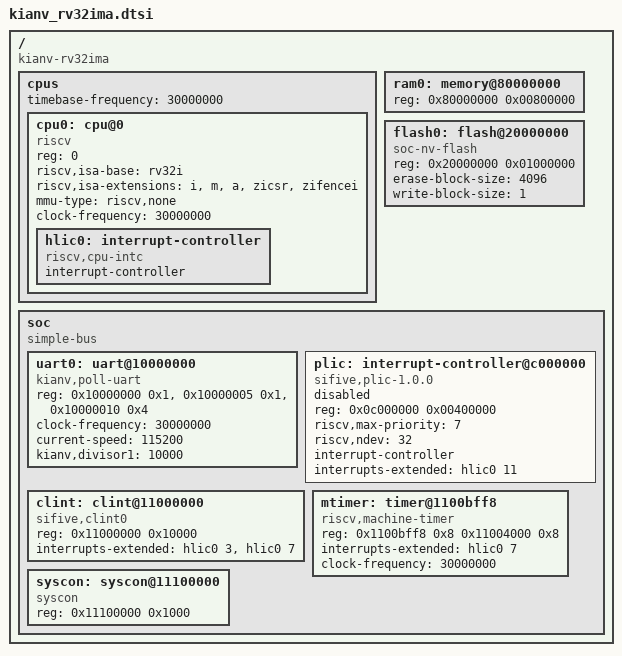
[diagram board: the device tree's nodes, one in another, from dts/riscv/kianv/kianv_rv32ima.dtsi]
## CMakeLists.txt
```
# SPDX-License-Identifier: Apache-2.0
# Copyright (c) 2026 Hirosh Dabui <hirosh@dabui.de>

cmake_minimum_required(VERSION 3.20.0)

list(APPEND BOARD_ROOT ${CMAKE_CURRENT_SOURCE_DIR})
list(APPEND SOC_ROOT ${CMAKE_CURRENT_SOURCE_DIR})
list(APPEND DTS_ROOT ${CMAKE_CURRENT_SOURCE_DIR})

file(MAKE_DIRECTORY ${CMAKE_BINARY_DIR}/Kconfig)
file(WRITE ${CMAKE_BINARY_DIR}/Kconfig/kconfig_module_dirs.cmake "set(kconfig_env_dirs)\n")

find_package(Zephyr REQUIRED HINTS $ENV{ZEPHYR_BASE})
project(kianv_asic_zephyr)

target_sources(app PRIVATE src/main.c)
target_sources(app PRIVATE drivers/serial/uart_kianv_poll.c)
```

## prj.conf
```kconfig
# SPDX-License-Identifier: Apache-2.0
# Copyright (c) 2026 Hirosh Dabui <hirosh@dabui.de>

CONFIG_PRINTK=y
CONFIG_CONSOLE=y
CONFIG_SERIAL=y
CONFIG_UART_CONSOLE=y
CONFIG_SHELL=y
CONFIG_SHELL_BACKEND_SERIAL=y
CONFIG_UART_INTERRUPT_DRIVEN=y
CONFIG_SHELL_BACKEND_SERIAL_INTERRUPT_DRIVEN=y
CONFIG_SHELL_BACKEND_SERIAL_API_POLLING=n
CONFIG_SHELL_BACKEND_SERIAL_RX_RING_BUFFER_SIZE=256
CONFIG_SHELL_PROMPT_UART="kianv:~$ "
CONFIG_SHELL_BACKEND_DUMMY=n
CONFIG_SHELL_VT100_COMMANDS=y
CONFIG_SHELL_VT100_COLORS=n
CONFIG_SHELL_BACKSPACE_MODE_DELETE=y
CONFIG_SHELL_HISTORY=y
CONFIG_SHELL_HISTORY_BUFFER=512
CONFIG_KERNEL_SHELL=y
CONFIG_DEVICE_SHELL=y
CONFIG_FILE_SYSTEM=y
CONFIG_FILE_SYSTEM_MKFS=y
CONFIG_FILE_SYSTEM_SHELL=y
CONFIG_FILE_SYSTEM_SHELL_TEST_COMMANDS=y
CONFIG_DISK_ACCESS=y
CONFIG_DISK_DRIVERS=y
CONFIG_DISK_DRIVER_RAM=y
CONFIG_FILE_SYSTEM_EXT2=y
CONFIG_EXT2_FSTAB_AUTOMOUNT=y
CONFIG_TEST_RANDOM_GENERATOR=y
CONFIG_TIMER_RANDOM_GENERATOR=y
CONFIG_HEAP_MEM_POOL_SIZE=2048

CONFIG_MAIN_STACK_SIZE=2048
CONFIG_ISR_STACK_SIZE=2048
CONFIG_IDLE_STACK_SIZE=512
CONFIG_SHELL_STACK_SIZE=6144

CONFIG_TIMESLICING=y
CONFIG_SYS_CLOCK_TICKS_PER_SEC=100

CONFIG_REBOOT=y
CONFIG_POWEROFF=y

CONFIG_BUILD_OUTPUT_BIN=y
CONFIG_MINIMAL_LIBC_OPTIMIZE_STRING_FOR_SIZE=n
```

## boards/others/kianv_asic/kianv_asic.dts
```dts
// SPDX-License-Identifier: Apache-2.0
/* Copyright (c) 2026 Hirosh Dabui <hirosh@dabui.de> */

/dts-v1/;

#include <kianv/kianv_rv32ima.dtsi>

/ {
	model = "KianV RV32IMA ASIC SoC";
	compatible = "kianv-asic";

	chosen {
		zephyr,console = &uart0;
		zephyr,shell-uart = &uart0;
		zephyr,sram = &ram0;
		zephyr,flash = &flash0;
	};

	fstab {
		compatible = "zephyr,fstab";

		ramfs: ramfs {
			compatible = "zephyr,fstab,ext2";
			automount;
			disk-access;
			disk-name = "RAM";
			mount-point = "/RAM";
		};
	};

	ramdisk0 {
		compatible = "zephyr,ram-disk";
		disk-name = "RAM";
		sector-size = <512>;
		sector-count = <128>;
	};
};
```

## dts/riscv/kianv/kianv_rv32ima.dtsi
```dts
// SPDX-License-Identifier: Apache-2.0
/* Copyright (c) 2026 Hirosh Dabui <hirosh@dabui.de> */

#include <skeleton.dtsi>

/ {
	#address-cells = <1>;
	#size-cells = <1>;
	compatible = "kianv-rv32ima";

	cpus {
		#address-cells = <1>;
		#size-cells = <0>;
		timebase-frequency = <30000000>;

		cpu0: cpu@0 {
			device_type = "cpu";
			reg = <0>;
			status = "okay";
			compatible = "riscv";
			riscv,isa-base = "rv32i";
			riscv,isa-extensions = "i", "m", "a", "zicsr", "zifencei";
			mmu-type = "riscv,none";
			clock-frequency = <30000000>;

			hlic0: interrupt-controller {
				compatible = "riscv,cpu-intc";
				#address-cells = <0>;
				#interrupt-cells = <1>;
				interrupt-controller;
			};
		};
	};

	ram0: memory@80000000 {
		device_type = "memory";
		reg = <0x80000000 0x00800000>;
	};

	flash0: flash@20000000 {
		compatible = "soc-nv-flash";
		reg = <0x20000000 0x01000000>;
		erase-block-size = <4096>;
		write-block-size = <1>;
	};

	soc {
		#address-cells = <1>;
		#size-cells = <1>;
		compatible = "simple-bus";
		ranges;

		uart0: uart@10000000 {
			compatible = "kianv,poll-uart";
			reg = <0x10000000 0x1>,
			      <0x10000005 0x1>,
			      <0x10000010 0x4>;
			reg-names = "data", "lsr", "div";
			clock-frequency = <30000000>;
			current-speed = <115200>;
			kianv,divisor1 = <10000>;
			status = "okay";
		};

		plic: interrupt-controller@c000000 {
			compatible = "sifive,plic-1.0.0";
			reg = <0x0c000000 0x00400000>;
			riscv,max-priority = <7>;
			riscv,ndev = <32>;
			interrupt-controller;
			#address-cells = <0>;
			#interrupt-cells = <2>;
			interrupts-extended = <&hlic0 11>;
			status = "disabled";
		};

		clint: clint@11000000 {
			compatible = "sifive,clint0";
			reg = <0x11000000 0x10000>;
			interrupts-extended = <&hlic0 3 &hlic0 7>;
			status = "okay";
		};

		mtimer: timer@1100bff8 {
			compatible = "riscv,machine-timer";
			reg = <0x1100bff8 0x8 0x11004000 0x8>;
			reg-names = "mtime", "mtimecmp";
			interrupts-extended = <&hlic0 7>;
			clock-frequency = <30000000>;
			status = "okay";
		};

		syscon: syscon@11100000 {
			compatible = "syscon";
			reg = <0x11100000 0x1000>;
			status = "okay";
		};
	};
};
```

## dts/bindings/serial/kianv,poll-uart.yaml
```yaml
# SPDX-License-Identifier: Apache-2.0
# Copyright (c) 2026 Hirosh Dabui <hirosh@dabui.de>

description: KianV polling MMIO UART

compatible: "kianv,poll-uart"

include: uart-controller.yaml

properties:
  reg:
    required: true

  reg-names:
    required: true

  kianv,divisor1:
    type: int
    default: 1000
    description: High-word divider used by the KianV UART divider register.
```

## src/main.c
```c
// SPDX-License-Identifier: Apache-2.0
/* Copyright (c) 2026 Hirosh Dabui <hirosh@dabui.de> */

#include <zephyr/kernel.h>
#include <zephyr/fs/fs.h>
#include <zephyr/storage/disk_access.h>
#include <zephyr/sys/printk.h>
#include <errno.h>

#define RAMFS_NODE DT_NODELABEL(ramfs)

FS_FSTAB_DECLARE_ENTRY(RAMFS_NODE);

int main(void)
{
	struct fs_mount_t *ram_mount = &FS_FSTAB_ENTRY(RAMFS_NODE);
	int rc;

	printk("Zephyr RTOS on KianV RV32IMA ASIC SoC\n");
	(void)disk_access_init("RAM");
	rc = fs_mount(ram_mount);
	if ((rc < 0) && (rc != -EALREADY) && (rc != -EBUSY)) {
		printk("RAM mount err %d\n", rc);
	}
	printk("Shell ready\n");
	return 0;
}
```
